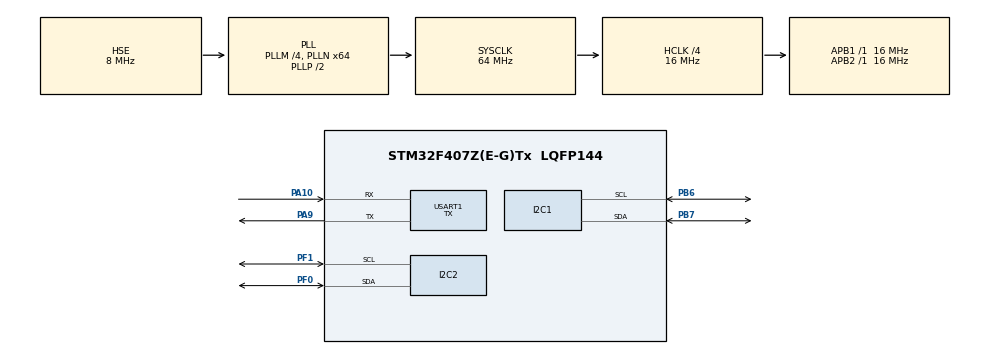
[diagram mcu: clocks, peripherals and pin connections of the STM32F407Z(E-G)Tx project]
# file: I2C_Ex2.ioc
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I2C2.OwnAddress=0x10
Mcu.Family=STM32F4
Mcu.Name=STM32F407Z(E-G)Tx
Mcu.Package=LQFP144
NVIC.I2C1_ER_IRQn=true\:0\:0\:false\:false\:true\:true\:true\:true
NVIC.I2C1_EV_IRQn=true\:0\:0\:false\:false\:true\:true\:true\:true
NVIC.I2C2_ER_IRQn=true\:0\:0\:false\:false\:true\:true\:true\:true
NVIC.I2C2_EV_IRQn=true\:0\:0\:false\:false\:true\:true\:true\:true
NVIC.PriorityGroup=NVIC_PRIORITYGROUP_4
PA10.Mode=Asynchronous
PA10.Signal=USART1_RX
PA13.Mode=Serial_Wire
PA13.Signal=SYS_JTMS-SWDIO
PA14.Mode=Serial_Wire
PA14.Signal=SYS_JTCK-SWCLK
PA9.Mode=Asynchronous
PA9.Signal=USART1_TX
PB6.GPIO_Pu=GPIO_PULLUP
PB6.Mode=I2C
PB6.Signal=I2C1_SCL
PB7.GPIO_Pu=GPIO_PULLUP
PB7.Mode=I2C
PB7.Signal=I2C1_SDA
PF0.Mode=I2C
PF0.Signal=I2C2_SDA
PF1.Mode=I2C
PF1.Signal=I2C2_SCL
PH0-OSC_IN.Mode=HSE-External-Oscillator
PH0-OSC_IN.Signal=RCC_OSC_IN
PH1-OSC_OUT.Mode=HSE-External-Oscillator
PH1-OSC_OUT.Signal=RCC_OSC_OUT
ProjectManager.HeapSize=0x200
ProjectManager.StackSize=0x400
ProjectManager.TargetToolchain=EWARM V8.50
RCC.48MHZClocksFreq_Value=32000000
RCC.AHBCLKDivider=RCC_SYSCLK_DIV4
RCC.AHBFreq_Value=16000000
RCC.APB1Freq_Value=16000000
RCC.APB1TimFreq_Value=16000000
RCC.APB2Freq_Value=16000000
RCC.APB2TimFreq_Value=16000000
RCC.CortexFreq_Value=16000000
RCC.HCLKFreq_Value=16000000
RCC.HSE_VALUE=8000000
RCC.HSI_VALUE=16000000
RCC.LSE_VALUE=32768
RCC.PLLM=4
RCC.PLLN=64
RCC.PLLSourceVirtual=RCC_PLLSOURCE_HSE
RCC.SYSCLKFreq_VALUE=64000000
RCC.SYSCLKSource=RCC_SYSCLKSOURCE_PLLCLK
RCC.VCOOutputFreq_Value=128000000
USART1.Mode=MODE_TX
USART1.VirtualMode=VM_ASYNC
board=custom

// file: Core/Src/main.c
/* USER CODE BEGIN Header */
/**
  ******************************************************************************
  * @file           : main.c
  * @brief          : Main program body
  ******************************************************************************
  * @attention
  *
  * Copyright (c) 2024 STMicroelectronics.
  * All rights reserved.
  *
  * This software is licensed under terms that can be found in the LICENSE file
  * in the root directory of this software component.
  * If no LICENSE file comes with this software, it is provided AS-IS.
  *
  ******************************************************************************
  */
/* USER CODE END Header */
#include "main.h"
#include "i2c.h"
#include "usart.h"
#include "gpio.h"

/* USER CODE BEGIN PV */
uint8_t i2cTransmit = 0;
uint8_t rxflag_i2c = 0;
/* USER CODE END PV */

void SystemClock_Config(void);

int main(void)
{

  /* USER CODE BEGIN 1 */
  char rxBuffer_i2c[15];
  /* USER CODE END 1 */

  /* MCU Configuration--------------------------------------------------------*/

  /* Reset of all peripherals, Initializes the Flash interface and the Systick. */
  HAL_Init();

  /* Configure the system clock */
  SystemClock_Config();

  /* Initialize all configured peripherals */
  MX_GPIO_Init();
  MX_I2C1_Init();
  MX_I2C2_Init();
  MX_USART1_UART_Init();
  /* USER CODE BEGIN 2 */
  HAL_I2C_EnableListen_IT(&hi2c2);
  /* USER CODE END 2 */

  /* Infinite loop */
  /* USER CODE BEGIN WHILE */
  while (1)
  {
    if(i2cTransmit)
    {
      i2cTransmit = 0;
      HAL_I2C_Master_Receive_IT(&hi2c1, 0x10<<1, (uint8_t *)rxBuffer_i2c, 15);
    }
    if(rxflag_i2c)
    {
      rxflag_i2c = 0;
      HAL_UART_Transmit(&huart1, (uint8_t *)rxBuffer_i2c, 15, 10);
    }
    /* USER CODE END WHILE */

  }
}

void SystemClock_Config(void)
{
  RCC_OscInitTypeDef RCC_OscInitStruct = {0};
  RCC_ClkInitTypeDef RCC_ClkInitStruct = {0};

  /** Configure the main internal regulator output voltage
  */
  __HAL_RCC_PWR_CLK_ENABLE();
  __HAL_PWR_VOLTAGESCALING_CONFIG(PWR_REGULATOR_VOLTAGE_SCALE1);

  /** Initializes the RCC Oscillators according to the specified parameters
  * in the RCC_OscInitTypeDef structure.
  */
  RCC_OscInitStruct.OscillatorType = RCC_OSCILLATORTYPE_HSE;
  RCC_OscInitStruct.HSEState = RCC_HSE_ON;
  RCC_OscInitStruct.PLL.PLLState = RCC_PLL_ON;
  RCC_OscInitStruct.PLL.PLLSource = RCC_PLLSOURCE_HSE;
  RCC_OscInitStruct.PLL.PLLM = 4;
  RCC_OscInitStruct.PLL.PLLN = 64;
  RCC_OscInitStruct.PLL.PLLP = RCC_PLLP_DIV2;
  RCC_OscInitStruct.PLL.PLLQ = 4;
  if (HAL_RCC_OscConfig(&RCC_OscInitStruct) != HAL_OK)
  {
    Error_Handler();
  }

  /** Initializes the CPU, AHB and APB buses clocks
  */
  RCC_ClkInitStruct.ClockType = RCC_CLOCKTYPE_HCLK|RCC_CLOCKTYPE_SYSCLK
                              |RCC_CLOCKTYPE_PCLK1|RCC_CLOCKTYPE_PCLK2;
  RCC_ClkInitStruct.SYSCLKSource = RCC_SYSCLKSOURCE_PLLCLK;
  RCC_ClkInitStruct.AHBCLKDivider = RCC_SYSCLK_DIV4;
  RCC_ClkInitStruct.APB1CLKDivider = RCC_HCLK_DIV1;
  RCC_ClkInitStruct.APB2CLKDivider = RCC_HCLK_DIV1;

  if (HAL_RCC_ClockConfig(&RCC_ClkInitStruct, FLASH_LATENCY_0) != HAL_OK)
  {
    Error_Handler();
  }
}

void Error_Handler(void)
{
  __disable_irq();
  while (1)
  {
  }
}
